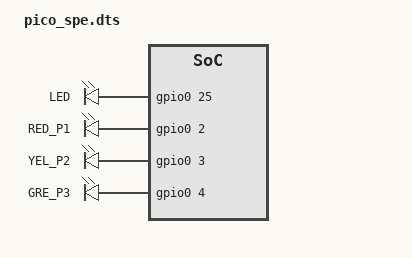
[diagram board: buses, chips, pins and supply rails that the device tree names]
/*
 * Copyright (c) 2024 KWS Computersysteme Gmbh
 *
 * SPDX-License-Identifier: Apache-2.0
 */

/dts-v1/;

#include "pico_spe-common.dtsi"

/ {
	leds {
		compatible = "gpio-leds";
		led0: led_0 {
			gpios = <&gpio0 25 GPIO_ACTIVE_HIGH>;
			label = "LED";
		};
		red1: red_p1 {
			gpios = <&gpio0 2 GPIO_ACTIVE_HIGH>;
			label = "RED_P1";
		};

		yellow2: yel_p2 {
			gpios = <&gpio0 3 GPIO_ACTIVE_HIGH>;
			label = "YEL_P2";
		};

		green3: gre_p3 {
			gpios = <&gpio0 4 GPIO_ACTIVE_HIGH>;
			label = "GRE_P3";
		};
	};

	pwm_leds {
		compatible = "pwm-leds";
		status = "disabled";
		pwm_led0: pwm_led_0 {
			pwms = <&pwm 9 PWM_MSEC(20) PWM_POLARITY_NORMAL>;
			label = "PWM_LED";
		};
	};

	aliases {
		led0 = &led0;
		red = &red1;
		yellow = &yellow2;
		green = &green3;
		pwm-led0 = &pwm_led0;
	};
};
